# M2354 register map
File version: 1.0
Registers are 32-bit, read-write, reset 0x0 unless marked. A register's access mark holds for its fields unless they carry their own. Offsets are from the block's base; [hi:lo] are bit positions; {n}, {i} and the like mark numbered series; 'fields as' and 'values as' point back to an identical list.

## SCU_NS — SCU Register Map
Base 0x5002F000
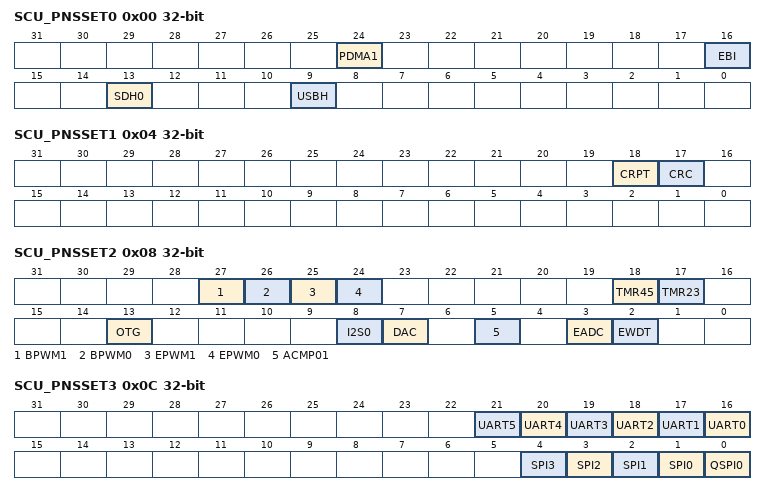
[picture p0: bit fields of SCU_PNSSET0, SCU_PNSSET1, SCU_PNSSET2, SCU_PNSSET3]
0x00 SCU_PNSSET0 — Peripheral Non-secure Attribution Set Register0 (0x4000_0000~0x4001_FFFF)
  [24] PDMA1 — Set PDMA1 to Non-secure State. Write 1 to set PDMA1 to non-secure state.
    0=PDMA1 is a secure module (default); 1=PDMA1 is a non-secure module
  [16] EBI — Set EBI to Non-secure State. Write 1 to set EBI to non-secure state.
    0=EBI is a secure module (default); 1=EBI is a non-secure module
  [13] SDH0 — Set SDH0 to Non-secure State. Write 1 to set SDH0 to non-secure state.
    0=SDH0 is a secure module (default); 1=SDH0 is a non-secure module
  [9] USBH — Set USBH to Non-secure State. Write 1 to set USBH to non-secure state.
    0=USBH is a secure module (default); 1=USBH is a non-secure module
0x04 SCU_PNSSET1 — Peripheral Non-secure Attribution Set Register1 (0x4002_0000~0x4003_FFFF)
  [18] CRPT — Set CRPT to Non-secure State
    0=CRPT is a secure module (default); 1=CRPT is a non-secure module
  [17] CRC — Set CRC to Non-secure State. Write 1 to set CRC to non-secure state.
    0=CRC is a secure module (default); 1=CRC is a non-secure module
0x08 SCU_PNSSET2 — Peripheral Non-secure Attribution Set Register2 (0x4004_0000~0x4005_FFFF)
  [27] BPWM1 — Set BPWM1 to Non-secure State. Write 1 to set BPWM1 to non-secure state.
    0=BPWM1 is a secure module (default); 1=BPWM1 is a non-secure module
  [26] BPWM0 — Set BPWM0 to Non-secure State. Write 1 to set BPWM0 to non-secure state.
    0=BPWM0 is a secure module (default); 1=BPWM0 is a non-secure module
  [25] EPWM1 — Set EPWM1 to Non-secure State. Write 1 to set EPWM1 to non-secure state.
    0=EPWM1 is a secure module (default); 1=EPWM1 is a non-secure module
  [24] EPWM0 — Set EPWM0 to Non-secure State. Write 1 to set EPWM0 to non-secure state.
    0=EPWM0 is a secure module (default); 1=EPWM0 is a non-secure module
  [18] TMR45 — Set TMR45 to Non-secure State. Write 1 to set TMR45 to non-secure state.
    0=TMR45 is a secure module (default); 1=TMR45 is a non-secure module
  [17] TMR23 — Set TMR23 to Non-secure State. Write 1 to set TMR23 to non-secure state.
    0=TMR23 is a secure module (default); 1=TMR23 is a non-secure module
  [13] OTG — Set OTG to Non-secure State. Write 1 to set OTG to non-secure state.
    0=OTG is a secure module (default); 1=OTG is a non-secure module
  [8] I2S0 — Set I2S0 to Non-secure State. Write 1 to set I2S0 to non-secure state.
    0=I2S0 is a secure module (default); 1=I2S0 is a non-secure module
  [7] DAC — Set DAC to Non-secure State. Write 1 to set DAC to non-secure state.
    0=DAC is a secure module (default); 1=DAC is a non-secure module
  [5] ACMP01 — Set ACMP01 to Non-secure State. Write 1 to set ACMP0, ACMP1 to non-secure state.
    0=ACMP0, ACMP1 are secure modules (default); 1=ACMP0, ACMP1 are non-secure modules
  [3] EADC — Set EADC to Non-secure State. Write 1 to set EADC to non-secure state.
    0=EADC is a secure module (default); 1=EADC is a non-secure module
  [2] EWDT — Set EWDT to Non-secure State. Write 1 to set EWDT to non-secure state.
    0=EWDT is a secure module (default); 1=EWDT is a non-secure module
0x0C SCU_PNSSET3 — Peripheral Non-secure Attribution Set Register3 (0x4006_0000~0x4007_FFFF)
  [n+16] UART{n} (n=0..5) — Set UART{n} to Non-secure State. Write 1 to set UART{n} to non-secure state.
    0=UART{n} is a secure module (default); 1=UART{n} is a non-secure module
  [n+1] SPI{n} (n=0..3) — Set SPI{n} to Non-secure State. Write 1 to set SPI{n} to non-secure state.
    0=SPI{n} is a secure module (default); 1=SPI{n} is a non-secure module
  [0] QSPI0 — Set QSPI0 to Non-secure State. Write 1 to set QSPI0 to non-secure state.
    0=QSPI0 is a secure module (default); 1=QSPI0 is a non-secure module
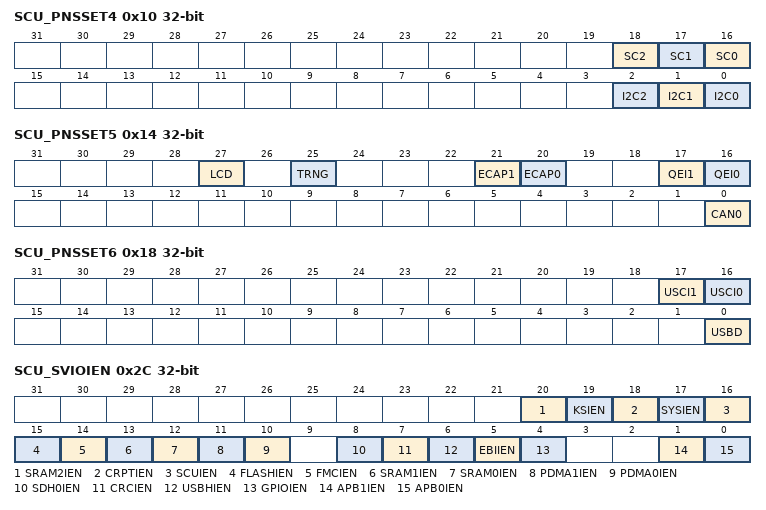
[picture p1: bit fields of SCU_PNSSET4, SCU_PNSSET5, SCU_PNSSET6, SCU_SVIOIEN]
0x10 SCU_PNSSET4 — Peripheral Non-secure Attribution Set Register4 (0x4008_0000~0x4009_FFFF)
  [18] SC2 — Set SC2 to Non-secure State. Write 1 to set SC2 to non-secure state.
    0=SC2 is a secure module (default); 1=SC2 is a non-secure module
  [17] SC1 — Set SC1 to Non-secure State. Write 1 to set SC1 to non-secure state.
    0=SC1 is a secure module (default); 1=SC1 is a non-secure module
  [16] SC0 — Set SC0 to Non-secure State. Write 1 to set SC0 to non-secure state.
    0=SC0 is a secure module (default); 1=SC0 is a non-secure module
  [2] I2C2 — Set I2C2 to Non-secure State. Write 1 to set I2C2 to non-secure state.
    0=I2C2 is a secure module (default); 1=I2C2 is a non-secure module
  [1] I2C1 — Set I2C1 to Non-secure State. Write 1 to set I2C1 to non-secure state.
    0=I2C1 is a secure module (default); 1=I2C1 is a non-secure module
  [0] I2C0 — Set I2C0 to Non-secure State. Write 1 to set I2C0 to non-secure state.
    0=I2C0 is a secure module (default); 1=I2C0 is a non-secure module
0x14 SCU_PNSSET5 — Peripheral Non-secure Attribution Set Register5 (0x400A_0000~0x400B_FFFF)
  [27] LCD — Set LCD to Non-secure State. Write 1 to set LCD to non-secure state.
    0=LCD is a secure module (default); 1=LCD is a non-secure module
  [25] TRNG — Set TRNG to Non-secure State. Write 1 to set TRNG to non-secure state.
    0=TRNG is a secure module (default); 1=TRNG is a non-secure module
  [21] ECAP1 — Set ECAP1 to Non-secure State. Write 1 to set ECAP1 to non-secure state.
    0=ECAP1 is a secure module (default); 1=ECAP1 is a non-secure module
  [20] ECAP0 — Set ECAP0 to Non-secure State. Write 1 to set ECAP0 to non-secure state.
    0=ECAP0 is a secure module (default); 1=ECAP0 is a non-secure module
  [17] QEI1 — Set QEI1 to Non-secure State. Write 1 to set QEI1 to non-secure state.
    0=QEI1 is a secure module (default); 1=QEI1 is a non-secure module
  [16] QEI0 — Set QEI0 to Non-secure State. Write 1 to set QEI0 to non-secure state.
    0=QEI0 is a secure module (default); 1=QEI0 is a non-secure module
  [0] CAN0 — Set CAN0 to Non-secure State. Write 1 to set CAN0 to non-secure state.
    0=CAN0 is a secure module (default); 1=CAN0 is a non-secure module
0x18 SCU_PNSSET6 — Peripheral Non-secure Attribution Set Register6 (0x400C_0000~0x400D_FFFF)
  [17] USCI1 — Set USCI1 to Non-secure State. Write 1 to set USCI1 to non-secure state.
    0=USCI1 is a secure module (default); 1=USCI1 is a non-secure module
  [16] USCI0 — Set USCI0 to Non-secure State. Write 1 to set USCI0 to non-secure state.
    0=USCI0 is a secure module (default); 1=USCI0 is a non-secure module
  [0] USBD — Set USBD to Non-secure State. Write 1 to set USBD to non-secure state.
    0=USBD is a secure module (default); 1=USBD is a non-secure module
0x24 SCU_SRAMNSSET — SRAM Non-secure Attribution Set Register
  [14:0] SECn — Set SRAM Section n to Non-secure State. Write 1 to set SRAM section n to non-secure state. Write 0 is ignored. Size per section is 16 Kbytes. Secure SRAM section n is 0x2000_0000+0x4000*n to 0x2000_0000+0x4000*(n+1)-0x1. Non-secure SRAM section n is 0x3000_0000+0x4000*n to 0x3000_0000+0x4000*(n+1)-0x1
    0=SRAM Section n is secure (default); 1=SRAM Section n is non-secure
0x28 SCU_FNSADDR ro reset not defined — Flash Non-secure Boundary Address Register
  [31:0] FNSADDR — Flash Non-secure Boundary Address. Indicate the base address of Non-secure region set in user configuration. Refer to FMC section for more details.
0x2C SCU_SVIOIEN — Security Violation Interrupt Enable Register
  [20] SRAM2IEN — SRAM2 Security Violation Interrupt Enable Bit
    0=Interrupt triggered from security violation of SRAM2 Disabled; 1=Interrupt triggered from security violation of SRAM2 Enabled
  [19] KSIEN — KS Security Violation Interrupt Enable Bit
    0=Interrupt triggered from security violation of keystore Disabled; 1=Interrupt triggered from security violation of keystore Enabled
  [18] CRPTIEN — CRPT Security Violation Interrupt Enable Bit
    0=Interrupt triggered from security violation of crypto Disabled; 1=Interrupt triggered from security violation of crypto Enabled
  [17] SYSIEN — SYS Security Violation Interrupt Enable Bit
    0=Interrupt triggered from security violation of system manager Disabled; 1=Interrupt triggered from security violation of system manager Enabled
  [16] SCUIEN — SCU Security Violation Interrupt Enable Bit
    0=Interrupt triggered from security violation of SCU Disabled; 1=Interrupt triggered from security violation of SCU Enabled
  [15] FLASHIEN — FLASH Security Violation Interrupt Enable Bit
    0=Interrupt triggered from security violation of Flash data Disabled; 1=Interrupt triggered from security violation of Flash data Enabled
  [14] FMCIEN — FMC Security Violation Interrupt Enable Bit
    0=Interrupt triggered from security violation of FMC Disabled; 1=Interrupt triggered from security violation of FMC Enabled
  [13] SRAM1IEN — SRAM Bank 1 Security Violation Interrupt Enable Bit
    0=Interrupt triggered from security violation of SRAM bank1 Disabled; 1=Interrupt triggered from security violation of SRAM bank1 Enabled
  [12] SRAM0IEN — SRAM Bank 0 Security Violation Interrupt Enable Bit
    0=Interrupt triggered from security violation of SRAM bank0 Disabled; 1=Interrupt triggered from security violation of SRAM bank0 Enabled
  [11] PDMA1IEN — PDMA1 Security Violation Interrupt Enable Bit
    0=Interrupt triggered from security violation of PDMA1 Disabled; 1=Interrupt triggered from security violation of PDMA1 Enabled
  [10] PDMA0IEN — PDMA0 Security Violation Interrupt Enable Bit
    0=Interrupt triggered from security violation of PDMA0 Disabled; 1=Interrupt triggered from security violation of PDMA0 Enabled
  [8] SDH0IEN — SDH0 Security Violation Interrupt Enable Bit
    0=Interrupt triggered from security violation of SD host 0 Disabled; 1=Interrupt triggered from security violation of SD host 0 Enabled
  [7] CRCIEN — CRC Security Violation Interrupt Enable Bit
    0=Interrupt triggered from security violation of CRC Disabled; 1=Interrupt triggered from security violation of CRC Enabled
  [6] USBHIEN — USBH Security Violation Interrupt Enable Bit
    0=Interrupt triggered from security violation of USB host Disabled; 1=Interrupt triggered from security violation of USB host Enabled
  [5] EBIIEN — EBI Security Violation Interrupt Enable Bit
    0=Interrupt triggered from security violation of EBI Disabled; 1=Interrupt triggered from security violation of EBI Enabled
  [4] GPIOIEN — GPIO Security Violation Interrupt Enable Bit
    0=Interrupt triggered from security violation of GPIO Disabled; 1=Interrupt triggered from security violation of GPIO Enabled
  [1] APB1IEN — APB1 Security Violation Interrupt Enable Bit
    0=Interrupt triggered from security violation of APB1 Disabled; 1=Interrupt triggered from security violation of APB1 Enabled
  [0] APB0IEN — APB0 Security Violation Interrupt Enable Bit
    0=Interrupt triggered from security violation of APB0 Disabled; 1=Interrupt triggered from security violation of APB0 Enabled
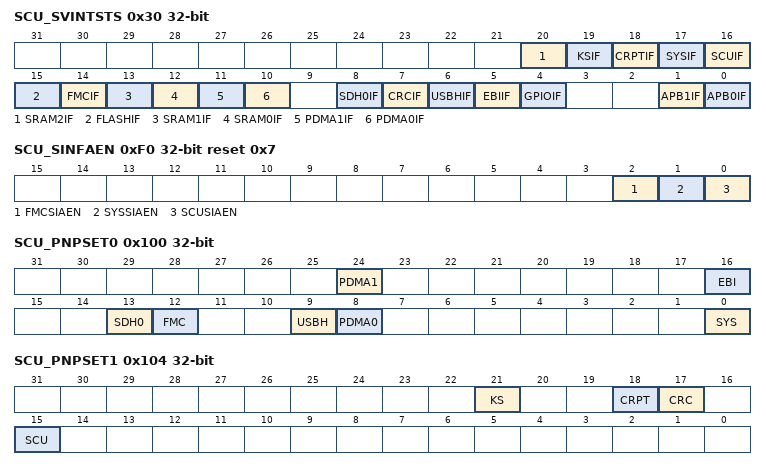
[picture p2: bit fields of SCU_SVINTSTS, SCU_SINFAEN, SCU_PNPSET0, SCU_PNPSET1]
0x30 SCU_SVINTSTS — Security Violation Interrupt Status Register
  [20] SRAM2IF — SRAM Bank 2 Security Violation Interrupt Status. Note: Write 1 to clear the interrupt flag.
    0=No SRAM Bank 2 violation interrupt event; 1=There is at least a SRAM Bank 2 violation interrupt event
  [19] KSIF — KS Security Violation Interrupt Status. Note: Write 1 to clear the interrupt flag.
    0=No KS violation interrupt event; 1=There is at least a KS violation interrupt event
  [18] CRPTIF — CRPT Security Violation Interrupt Status. Note: Write 1 to clear the interrupt flag.
    0=No CRPT violation interrupt event; 1=There is at least a CRPT violation interrupt event
  [17] SYSIF — SYS Security Violation Interrupt Status. Note: Write 1 to clear the interrupt flag.
    0=No SYS violation interrupt event; 1=There is at least a SYS violation interrupt event
  [16] SCUIF — SCU Security Violation Interrupt Status. Note: Write 1 to clear the interrupt flag.
    0=No SCU violation interrupt event; 1=There is at least a SCU violation interrupt event
  [15] FLASHIF — FLASH Security Violation Interrupt Status. Note: Write 1 to clear the interrupt flag.
    0=No FLASH violation interrupt event; 1=There is at least a FLASH violation interrupt event
  [14] FMCIF — FMC Security Violation Interrupt Status. Note: Write 1 to clear the interrupt flag.
    0=No FMC violation interrupt event; 1=There is at least a FMC violation interrupt event
  [13] SRAM1IF — SRAM Bank 1 Security Violation Interrupt Status. Note: Write 1 to clear the interrupt flag.
    0=No SRAM Bank 1 violation interrupt event; 1=There is at least a SRAM Bank 1 violation interrupt event
  [12] SRAM0IF — SRAM Bank 0 Security Violation Interrupt Status. Note: Write 1 to clear the interrupt flag.
    0=No SRAM Bank 0 violation interrupt event; 1=There is at least a SRAM Bank 0 violation interrupt event
  [11] PDMA1IF — PDMA1 Security Violation Interrupt Status. Note: Write 1 to clear the interrupt flag.
    0=No PDMA1 violation interrupt event; 1=There is at least a PDMA1 violation interrupt event
  [10] PDMA0IF — PDMA0 Security Violation Interrupt Status. Note: Write 1 to clear the interrupt flag.
    0=No PDMA0 violation interrupt event; 1=There is at least a PDMA0 violation interrupt event
  [8] SDH0IF — SDH0 Security Violation Interrupt Status. Note: Write 1 to clear the interrupt flag.
    0=No SDH0 violation interrupt event; 1=There is at least a SDH0 violation interrupt event
  [7] CRCIF — CRC Security Violation Interrupt Status. Note: Write 1 to clear the interrupt flag.
    0=No CRC violation interrupt event; 1=There is at least a CRC violation interrupt event
  [6] USBHIF — USBH Security Violation Interrupt Status. Note: Write 1 to clear the interrupt flag.
    0=No USBH violation interrupt event; 1=There is at least a USBH violation interrupt event
  [5] EBIIF — EBI Security Violation Interrupt Status. Note: Write 1 to clear the interrupt flag.
    0=No EBI violation interrupt event; 1=There is at least a EBI violation interrupt event
  [4] GPIOIF — GPIO Security Violation Interrupt Status. Note: Write 1 to clear the interrupt flag.
    0=No GPIO violation interrupt event; 1=There is at least a GPIO violation interrupt event
  [1] APB1IF — APB1 Security Violation Interrupt Status. Note: Write 1 to clear the interrupt flag.
    0=No APB1 violation interrupt event; 1=There is at least a APB1 violation interrupt event
  [0] APB0IF — APB0 Security Violation Interrupt Status. Note: Write 1 to clear the interrupt flag.
    0=No APB0 violation interrupt event; 1=There is at least a APB0 violation interrupt event
0x34 SCU_APB0VSRC ro (reset mask 0xFFFFFFF0) — APB0 Security Policy Violation Source
  [3:0] MASTER — Master Violating Security Policy. Indicate which master invokes the security violation. Others is undefined.
    0=core processor; 3=PDMA0; 4=SDH0; 5=CRYPTO; 6=USH; 11=PDMA1
0x38 SCU_APB0VA ro reset not defined — APB0 Violation Address
  [31:0] VIOADDR — Violation Address. Indicate the target address of the access, which invokes the security violation.
0x3C SCU_APB1VSRC ro (reset mask 0xFFFFFFF0) — APB1 Security Policy Violation Source
  fields as SCU_APB0VSRC
0x40 SCU_APB1VA ro reset not defined — APB1 Violation Address
  fields as SCU_APB0VA
0x44 SCU_GPIOVSRC ro (reset mask 0xFFFFFFF0) — GPIO Security Policy Violation Source
  fields as SCU_APB0VSRC
0x48 SCU_GPIOVA ro reset not defined — GPIO Violation Address
  fields as SCU_APB0VA
0x4C SCU_EBIVSRC ro (reset mask 0xFFFFFFF0) — EBI Security Policy Violation Source
  fields as SCU_APB0VSRC
0x50 SCU_EBIVA ro reset not defined — EBI Violation Address
  fields as SCU_APB0VA
0x54 SCU_USBHVSRC ro (reset mask 0xFFFFFFF0) — USBH Security Policy Violation Source
  fields as SCU_APB0VSRC
0x58 SCU_USBHVA ro reset not defined — USBH Violation Address
  fields as SCU_APB0VA
0x5C SCU_CRCVSRC ro (reset mask 0xFFFFFFF0) — CRC Security Policy Violation Source
  fields as SCU_APB0VSRC
0x60 SCU_CRCVA ro reset not defined — CRC Violation Address
  fields as SCU_APB0VA
0x64 SCU_SD0VSRC ro (reset mask 0xFFFFFFF0) — SDH0 Security Policy Violation Source
  fields as SCU_APB0VSRC
0x68 SCU_SD0VA ro reset not defined — SDH0 Violation Address
  fields as SCU_APB0VA
0x74 SCU_PDMA0VSRC ro (reset mask 0xFFFFFFF0) — PDMA0 Security Policy Violation Source
  fields as SCU_APB0VSRC
0x78 SCU_PDMA0VA ro reset not defined — PDMA0 Violation Address
  fields as SCU_APB0VA
0x7C SCU_PDMA1VSRC ro (reset mask 0xFFFFFFF0) — PDMA1 Security Policy Violation Source
  fields as SCU_APB0VSRC
0x80 SCU_PDMA1VA ro reset not defined — PDMA1 Violation Address
  fields as SCU_APB0VA
0x84 SCU_SRAM0VSRC ro (reset mask 0xFFFFFFF0) — SRAM0 Security Policy Violation Source
  fields as SCU_APB0VSRC
0x88 SCU_SRAM0VA ro reset not defined — SRAM0 Violation Address
  fields as SCU_APB0VA
0x8C SCU_SRAM1VSRC ro (reset mask 0xFFFFFFF0) — SRAM1 Security Policy Violation Source
  fields as SCU_APB0VSRC
0x90 SCU_SRAM1VA ro reset not defined — SRAM1 Violation Address
  fields as SCU_APB0VA
0x94 SCU_FMCVSRC ro (reset mask 0xFFFFFFF0) — FMC Security Policy Violation Source
  fields as SCU_APB0VSRC
0x98 SCU_FMCVA ro reset not defined — FMC Violation Address
  fields as SCU_APB0VA
0x9C SCU_FLASHVSRC ro (reset mask 0xFFFFFFF0) — Flash Security Policy Violation Source
  fields as SCU_APB0VSRC
0xA0 SCU_FLASHVA ro reset not defined — Flash Violation Address
  fields as SCU_APB0VA
0xA4 SCU_SCUVSRC ro (reset mask 0xFFFFFFF0) — SCU Security Policy Violation Source
  fields as SCU_APB0VSRC
0xA8 SCU_SCUVA ro reset not defined — SCU Violation Address
  fields as SCU_APB0VA
0xAC SCU_SYSVSRC ro (reset mask 0xFFFFFFF0) — System Security Policy Violation Source
  fields as SCU_APB0VSRC
0xB0 SCU_SYSVA ro reset not defined — System Violation Address
  fields as SCU_APB0VA
0xB4 SCU_CRPTVSRC ro (reset mask 0xFFFFFFF0) — Crypto Security Policy Violation Source
  fields as SCU_APB0VSRC
0xB8 SCU_CRPTVA ro reset not defined — Crypto Violation Address
  fields as SCU_APB0VA
0xBC SCU_KSVSRC ro (reset mask 0xFFFFFFF0) — KS Security Policy Violation Source
  fields as SCU_APB0VSRC
0xC0 SCU_KSVA ro reset not defined — KS Violation Address
  fields as SCU_APB0VA
0xC4 SCU_SRAM2VSRC ro (reset mask 0xFFFFFFF0) — SRAM2 Security Policy Violation Source
  fields as SCU_APB0VSRC
0xC8 SCU_SRAM2VA ro reset not defined — SRAM2 Violation Address
  fields as SCU_APB0VA
0xF0 SCU_SINFAEN reset 0x7 — Shared Information Access Enable Register
  [2] FMCSIAEN — FMC Shared Information Access Enable Bit
    0=Non-secure CPU access FMC Shared information Disabled; 1=Non-secure CPU access FMC Shared information Enabled
  [1] SYSSIAEN — SYS Shared Information Access Enable Bit. Note: Include clock information.
    0=Non-secure CPU access SYS Shared information Disabled; 1=Non-secure CPU access SYS Shared information Enabled
  [0] SCUSIAEN — SCU Shared Information Access Enable Bit
    0=Non-secure CPU access SCU Shared information Disabled; 1=Non-secure CPU access SCU Shared information Enabled
0x100 SCU_PNPSET0 — Peripheral Non-privileged Attribution Set Register0 (0x4000_0000~0x4001_FFFF)
  [24] PDMA1 — Set PDMA1 to Non-privileged State
    0=PDMA1 is a privileged module (default); 1=PDMA1 is a non-privileged module
  [16] EBI — Set EBI to Non-privileged State
    0=EBI is a privileged module (default); 1=EBI is a non-privileged module
  [13] SDH0 — Set SDH0 to Non-privileged State
    0=SDH0 is a privileged module (default); 1=SDH0 is a non-privileged module
  [12] FMC — Set FMC to Non-privileged State
    0=FMC is a privileged module (default); 1=FMC is a non-privileged module
  [9] USBH — Set USBH to Non-privileged State
    0=USBH is a privileged module (default); 1=USBH is a non-privileged module
  [8] PDMA0 — Set PDMA0 to Non-privileged State
    0=PDMA0 is a privileged module (default); 1=PDMA0 is a non-privileged module
  [0] SYS — Set SYS to Non-privileged State
    0=SYS is a privileged module (default); 1=SYS is a non-privileged module
0x104 SCU_PNPSET1 — Peripheral Non-privileged Attribution Set Register1 (0x4002_0000~0x4003_FFFF)
  [21] KS — Set KS to Non-privileged State
    0=KS is a privileged module (default); 1=KS is a non-privileged module
  [18] CRPT — Set CRPT to Non-privileged State
    0=CRPT is a privileged module (default); 1=CRPT is a non-privileged module
  [17] CRC — Set CRC to Non-privileged State
    0=CRC is a privileged module (default); 1=CRC is a non-privileged module
  [15] SCU — Set SCU to Non-privileged State
    0=SCU is a privileged module (default); 1=SCU is a non-privileged module
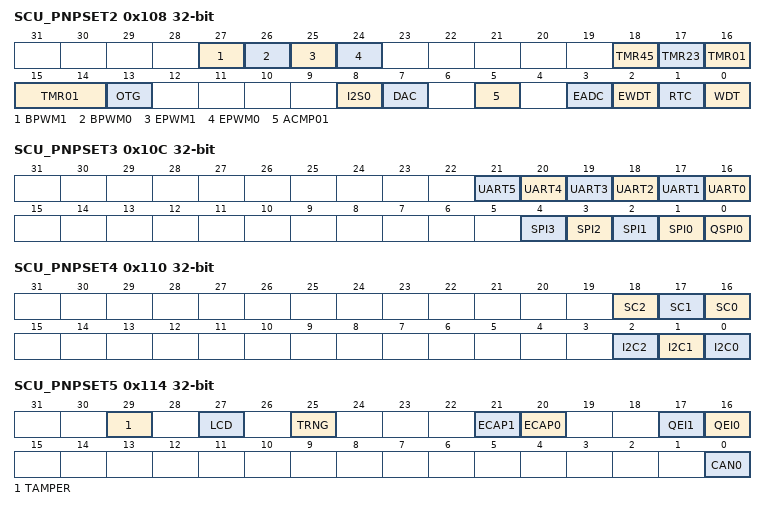
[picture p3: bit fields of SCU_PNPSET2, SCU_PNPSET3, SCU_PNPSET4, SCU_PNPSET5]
0x108 SCU_PNPSET2 — Peripheral Non-privileged Attribution Set Register2 (0x4004_0000~0x4005_FFFF)
  [27] BPWM1 — Set BPWM1 to Non-privileged State
    0=BPWM1 is a privileged module (default); 1=BPWM1 is a non-privileged module
  [26] BPWM0 — Set BPWM0 to Non-privileged State
    0=BPWM0 is a privileged module (default); 1=BPWM0 is a non-privileged module
  [25] EPWM1 — Set EPWM1 to Non-privileged State
    0=EPWM1 is a privileged module (default); 1=EPWM1 is a non-privileged module
  [24] EPWM0 — Set EPWM0 to Non-privileged State
    0=EPWM0 is a privileged module (default); 1=EPWM0 is a non-privileged module
  [18] TMR45 — Set TMR45 to Non-privileged State
    0=TMR45 is a privileged module (default); 1=TMR45 is a non-privileged module
  [17] TMR23 — Set TMR23 to Non-privileged State
    0=TMR23 is a privileged module (default); 1=TMR23 is a non-privileged module
  [16:14] TMR01 — Set TMR01 to Non-privileged State
    0=TMR01 is a privileged module (default); 1=TMR01 is a non-privileged module
  [13] OTG — Set OTG to Non-privileged State
    0=OTG is a privileged module (default); 1=OTG is a non-privileged module
  [8] I2S0 — Set I2S0 to Non-privileged State
    0=I2S0 is a privileged module (default); 1=I2S0 is a non-privileged module
  [7] DAC — Set DAC to Non-privileged State
    0=DAC is a privileged module (default); 1=DAC is a non-privileged module
  [5] ACMP01 — Set ACMP01 to Non-privileged State
    0=ACMP0, ACMP1 are privileged modules (default); 1=ACMP0, ACMP1 are non-privileged modules
  [3] EADC — Set EADC to Non-privileged State
    0=EADC is a privileged module (default); 1=EADC is a non-privileged module
  [2] EWDT — Set EWDT to Non-privileged State
    0=EWDT is a privileged module (default); 1=EWDT is a non-privileged module
  [1] RTC — Set RTC to Non-privileged State
    0=RTC is a privileged module (default); 1=RTC is a non-privileged module
  [0] WDT — Set WDT to Non-privileged State
    0=WDT is a privileged module (default); 1=WDT is a non-privileged module
0x10C SCU_PNPSET3 — Peripheral Non-privileged Attribution Set Register3 (0x4006_0000~0x4007_FFFF)
  [n+16] UART{n} (n=0..5) — Set UART{n} to Non-privileged State
    0=UART{n} is a privileged module (default); 1=UART{n} is a non-privileged module
  [n+1] SPI{n} (n=0..3) — Set SPI{n} to Non-privileged State
    0=SPI{n} is a privileged module (default); 1=SPI{n} is a non-privileged module
  [0] QSPI0 — Set QSPI0 to Non-privileged State
    0=QSPI0 is a privileged module (default); 1=QSPI0 is a non-privileged module
0x110 SCU_PNPSET4 — Peripheral Non-privileged Attribution Set Register4 (0x4008_0000~0x4009_FFFF)
  [18] SC2 — Set SC2 to Non-privileged State
    0=SC2 is a privileged module (default); 1=SC2 is a non-privileged module
  [17] SC1 — Set SC1 to Non-privileged State
    0=SC1 is a privileged module (default); 1=SC1 is a non-privileged module
  [16] SC0 — Set SC0 to Non-privileged State
    0=SC0 is a privileged module (default); 1=SC0 is a non-privileged module
  [2] I2C2 — Set I2C2 to Non-privileged State
    0=I2C2 is a privileged module (default); 1=I2C2 is a non-privileged module
  [1] I2C1 — Set I2C1 to Non-privileged State
    0=I2C1 is a privileged module (default); 1=I2C1 is a non-privileged module
  [0] I2C0 — Set I2C0 to Non-privileged State
    0=I2C0 is a privileged module (default); 1=I2C0 is a non-privileged module
0x114 SCU_PNPSET5 — Peripheral Non-privileged Attribution Set Register5 (0x400A_0000~0x400B_FFFF)
  [29] TAMPER — Set TAMPER to Non-privileged State
    0=TAMPER is a privileged module (default); 1=TAMPER is a non-privileged module
  [27] LCD — Set LCD to Non-privileged State
    0=LCD is a privileged module (default); 1=LCD is a non-privileged module
  [25] TRNG — Set TRNG to Non-privileged State
    0=TRNG is a privileged module (default); 1=TRNG is a non-privileged module
  [21] ECAP1 — Set ECAP1 to Non-privileged State
    0=ECAP1 is a privileged module (default); 1=ECAP1 is a non-privileged module
  [20] ECAP0 — Set ECAP0 to Non-privileged State
    0=ECAP0 is a privileged module (default); 1=ECAP0 is a non-privileged module
  [17] QEI1 — Set QEI1 to Non-privileged State
    0=QEI1 is a privileged module (default); 1=QEI1 is a non-privileged module
  [16] QEI0 — Set QEI0 to Non-privileged State
    0=QEI0 is a privileged module (default); 1=QEI0 is a non-privileged module
  [0] CAN0 — Set CAN0 to Non-privileged State
    0=CAN0 is a privileged module (default); 1=CAN0 is a non-privileged module
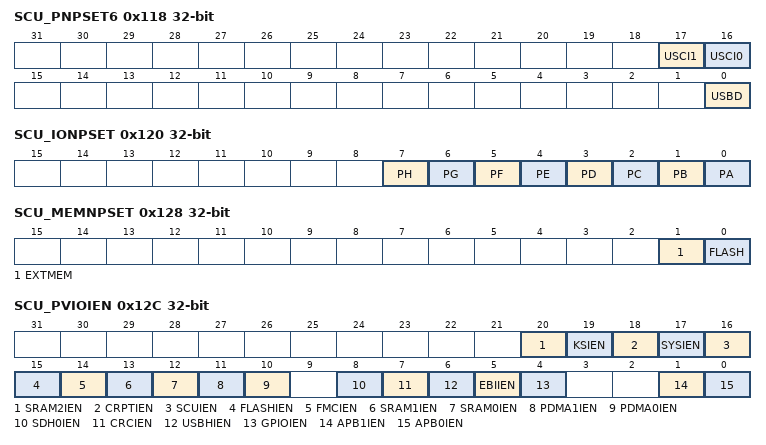
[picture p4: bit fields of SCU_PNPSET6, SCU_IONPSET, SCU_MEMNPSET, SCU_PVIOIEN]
0x118 SCU_PNPSET6 — Peripheral Non-privileged Attribution Set Register6 (0x400C_0000~0x400D_FFFF)
  [17] USCI1 — Set USCI1 to Non-privileged State
    0=USCI1 is a privileged module (default); 1=USCI1 is a non-privileged module
  [16] USCI0 — Set USCI0 to Non-privileged State
    0=USCI0 is a privileged module (default); 1=USCI0 is a non-privileged module
  [0] USBD — Set USBD to Non-privileged State
    0=USBD is a privileged module (default); 1=USBD is a non-privileged module
0x120 SCU_IONPSET — I/O Non-privileged Attribution Set Register
  [7] PH — Set GPIO Port H to Non-privileged State
    0=GPIO port H is privileged (default); 1=GPIO port H is non-privileged
  [6] PG — Set GPIO Port G to Non-privileged State
    0=GPIO port G is privileged (default); 1=GPIO port G is non-privileged
  [5] PF — Set GPIO Port F to Non-privileged State
    0=GPIO port F is privileged (default); 1=GPIO port F is non-privileged
  [4] PE — Set GPIO Port E to Non-privileged State
    0=GPIO port E is privileged (default); 1=GPIO port E is non-privileged
  [3] PD — Set GPIO Port D to Non-privileged State
    0=GPIO port D is privileged (default); 1=GPIO port D is non-privileged
  [2] PC — Set GPIO Port C to Non-privileged State
    0=GPIO port C is privileged (default); 1=GPIO port C is non-privileged
  [1] PB — Set GPIO Port B to Non-privileged State
    0=GPIO port B is privileged (default); 1=GPIO port B is non-privileged
  [0] PA — Set GPIO Port a to Non-privileged State
    0=GPIO port A is privileged (default); 1=GPIO port A is non-privileged
0x124 SCU_SRAMNPSET — SRAM Non-privileged Attribution Set Register
  [15:0] SECn — Set SRAM Section n to Non-privileged State. Size per section is 16 Kbytes. Secure SRAM section n is 0x2000_0000+0x4000*n to 0x2000_0000+0x4000*(n+1)-0x1. Non-secure SRAM section n is 0x3000_0000+0x4000*n to 0x3000_0000+0x4000*(n+1)-0x1
    0=SRAM Section n is privileged (default); 1=SRAM Section n is non-privileged
0x128 SCU_MEMNPSET — Other Memory Non-privileged Attribution Set Register
  [1] EXTMEM — Set External Memory (EBI Memory) to Non-privileged State. Set the privileged state of memory ranging from 0x6000_0000 to 0x7FFF_FFFF.
    0=External Memory is set to privileged (default); 1=External Memory is set to non-privileged
  [0] FLASH — Set Flash to Non-privileged State. Set the privileged state of memory ranging from 0x0000_0000 to 0x1FFF_FFFF.
    0=Flash is set to privileged (default); 1=Flash is set to non-privileged
0x12C SCU_PVIOIEN — Privileged Violation Interrupt Enable Register
  [20] SRAM2IEN — SRAM2 Privileged Violation Interrupt Enable Bit
    0=Interrupt triggered from privileged violation of SRAM2 Disabled; 1=Interrupt triggered from privileged violation of SRAM2 Enabled
  [19] KSIEN — KS Privileged Violation Interrupt Enable Bit
    0=Interrupt triggered from privileged violation of keystore Disabled; 1=Interrupt triggered from privileged violation of keystore Enabled
  [18] CRPTIEN — CRPT Privileged Violation Interrupt Enable Bit
    0=Interrupt triggered from privileged violation of crypto Disabled; 1=Interrupt triggered from privileged violation of crypto Enabled
  [17] SYSIEN — SYS Privileged Violation Interrupt Enable Bit
    0=Interrupt triggered from privileged violation of system manager Disabled; 1=Interrupt triggered from privileged violation of system manager Enabled
  [16] SCUIEN — SCU Privileged Violation Interrupt Enable Bit
    0=Interrupt triggered from privileged violation of SCU Disabled; 1=Interrupt triggered from privileged violation of SCU Enabled
  [15] FLASHIEN — FLASH Privileged Violation Interrupt Enable Bit
    0=Interrupt triggered from privileged violation of Flash data Disabled; 1=Interrupt triggered from privileged violation of Flash data Enabled
  [14] FMCIEN — FMC Privileged Violation Interrupt Enable Bit
    0=Interrupt triggered from privileged violation of FMC Disabled; 1=Interrupt triggered from privileged violation of FMC Enabled
  [13] SRAM1IEN — SRAM Bank 1 Privileged Violation Interrupt Enable Bit
    0=Interrupt triggered from privileged violation of SRAM bank1 Disabled; 1=Interrupt triggered from privileged violation of SRAM bank1 Enabled
  [12] SRAM0IEN — SRAM Bank 0 Privileged Violation Interrupt Enable Bit
    0=Interrupt triggered from privileged violation of SRAM bank0 Disabled; 1=Interrupt triggered from privileged violation of SRAM bank0 Enabled
  [11] PDMA1IEN — PDMA1 Privileged Violation Interrupt Enable Bit
    0=Interrupt triggered from privileged violation of PDMA1 Disabled; 1=Interrupt triggered from privileged violation of PDMA1 Enabled
  [10] PDMA0IEN — PDMA0 Privileged Violation Interrupt Enable Bit
    0=Interrupt triggered from privileged violation of PDMA0 Disabled; 1=Interrupt triggered from privileged violation of PDMA0 Enabled
  [8] SDH0IEN — SDH0 Privileged Violation Interrupt Enable Bit
    0=Interrupt triggered from privileged violation of SD host 0 Disabled; 1=Interrupt triggered from privileged violation of SD host 0 Enabled
  [7] CRCIEN — CRC Privileged Violation Interrupt Enable Bit
    0=Interrupt triggered from privileged violation of CRC Disabled; 1=Interrupt triggered from privileged violation of CRC Enabled
  [6] USBHIEN — USBH Privileged Violation Interrupt Enable Bit
    0=Interrupt triggered from privileged violation of USB host Disabled; 1=Interrupt triggered from privileged violation of USB host Enabled
  [5] EBIIEN — EBI Privileged Violation Interrupt Enable Bit
    0=Interrupt triggered from privileged violation of EBI Disabled; 1=Interrupt triggered from privileged violation of EBI Enabled
  [4] GPIOIEN — GPIO Privileged Violation Interrupt Enable Bit
    0=Interrupt triggered from privileged violation of GPIO Disabled; 1=Interrupt triggered from privileged violation of GPIO Enabled
  [1] APB1IEN — APB1 Privileged Violation Interrupt Enable Bit
    0=Interrupt triggered from privileged violation of APB1 Disabled; 1=Interrupt triggered from privileged violation of APB1 Enabled
  [0] APB0IEN — APB0 Privileged Violation Interrupt Enable Bit
    0=Interrupt triggered from privileged violation of APB0 Disabled; 1=Interrupt triggered from privileged violation of APB0 Enabled
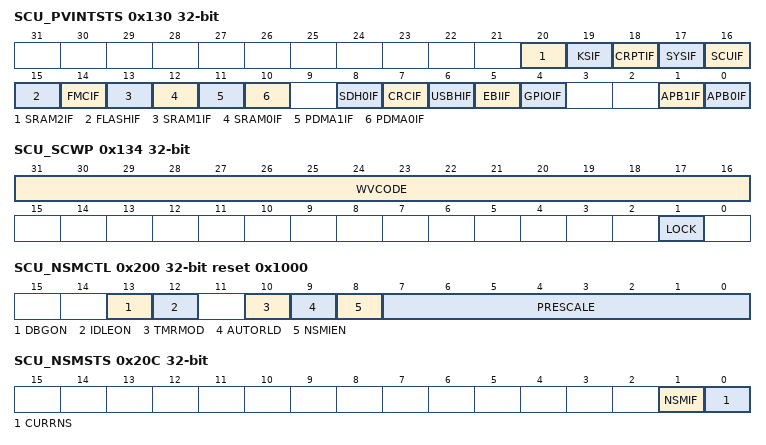
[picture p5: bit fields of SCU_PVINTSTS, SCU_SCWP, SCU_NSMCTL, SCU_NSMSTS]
0x130 SCU_PVINTSTS — Privileged Violation Interrupt Status Register
  [20] SRAM2IF — SRAM Bank 2 Privileged Violation Interrupt Status. Note: Write 1 to clear the interrupt flag.
    0=No SRAM Bank 2 violation interrupt event; 1=There is SRAM Bank 2 violation interrupt event
  [19] KSIF — KS Privileged Violation Interrupt Status. Note: Write 1 to clear the interrupt flag.
    0=No KS violation interrupt event; 1=There is KS violation interrupt event
  [18] CRPTIF — CRPT Privileged Violation Interrupt Status. Note: Write 1 to clear the interrupt flag.
    0=No CRPT violation interrupt event; 1=There is CRPT violation interrupt event
  [17] SYSIF — SYS Privileged Violation Interrupt Status. Note: Write 1 to clear the interrupt flag.
    0=No SYS violation interrupt event; 1=There is SYS violation interrupt event
  [16] SCUIF — SCU Privileged Violation Interrupt Status. Note: Write 1 to clear the interrupt flag.
    0=No SCU violation interrupt event; 1=There is SCU violation interrupt event
  [15] FLASHIF — FLASH Privileged Violation Interrupt Status. Note: Write 1 to clear the interrupt flag.
    0=No FLASH violation interrupt event; 1=There is FLASH violation interrupt event
  [14] FMCIF — FMC Privileged Violation Interrupt Status. Note: Write 1 to clear the interrupt flag.
    0=No FMC violation interrupt event; 1=There is FMC violation interrupt event
  [13] SRAM1IF — SRAM Bank 1 Privileged Violation Interrupt Status. Note: Write 1 to clear the interrupt flag.
    0=No SRAM1 violation interrupt event; 1=There is SRAM1 violation interrupt event
  [12] SRAM0IF — SRAM0 Privileged Violation Interrupt Status. Note: Write 1 to clear the interrupt flag.
    0=No SRAM0 violation interrupt event; 1=There is SRAM0 violation interrupt event
  [11] PDMA1IF — PDMA1 Privileged Violation Interrupt Status. Note: Write 1 to clear the interrupt flag.
    0=No PDMA1 violation interrupt event; 1=There is PDMA1 violation interrupt event
  [10] PDMA0IF — PDMA0 Privileged Violation Interrupt Status. Note: Write 1 to clear the interrupt flag.
    0=No PDMA0 violation interrupt event; 1=There is PDMA0 violation interrupt event
  [8] SDH0IF — SDH0 Privileged Violation Interrupt Status. Note: Write 1 to clear the interrupt flag.
    0=No SDH0 violation interrupt event; 1=There is SDH0 violation interrupt event
  [7] CRCIF — CRC Privileged Violation Interrupt Status. Note: Write 1 to clear the interrupt flag.
    0=No CRC violation interrupt event; 1=There is CRC violation interrupt event
  [6] USBHIF — USBH Privileged Violation Interrupt Status. Note: Write 1 to clear the interrupt flag.
    0=No USBH violation interrupt event; 1=There is USBH violation interrupt event
  [5] EBIIF — EBI Privileged Violation Interrupt Status. Note: Write 1 to clear the interrupt flag.
    0=No EBI violation interrupt event; 1=There is EBI violation interrupt event
  [4] GPIOIF — GPIO Privileged Violation Interrupt Status. Note: Write 1 to clear the interrupt flag.
    0=No GPIO violation interrupt event; 1=There is GPIO violation interrupt event
  [1] APB1IF — APB1 Privileged Violation Interrupt Status. Note: Write 1 to clear the interrupt flag.
    0=No APB1 violation interrupt event; 1=There is APB1 violation interrupt event
  [0] APB0IF — APB0 Privileged Violation Interrupt Status. Note: Write 1 to clear the interrupt flag.
    0=No APB0 violation interrupt event; 1=There is APB0 violation interrupt event
0x134 SCU_SCWP — Security Configuration Write Protection Register
  [31:16] WVCODE — Write Verify Code. Read operation: Reserved, all zeros. Write operation:
    0x475A=The write verify code, 0x475A, is needed to do a valid write to SCU_SCWP
  [1] LOCK — Enable Write Protection Lock Bit (Write One Only). Note: This bit cannot be cleared to 0 without a system-level reset after set to one.
    0=Write protection lock Disabled; 1=Write protection Enabled and locked
0x140 SCU_IONSSET0 — I/O Non-secure Attribution Set Register0
  [15:0] PA — Set GPIO Port A to Non-secure State. Write 1 to set PA to non-secure state. Each bit configures one pin in GPIO port A.
    0=GPIO port A is secure (default); 1=GPIO port A is non-secure
0x144 SCU_IONSSET1 — I/O Non-secure Attribution Set Register1
  [15:0] PB — Set GPIO Port B to Non-secure State. Write 1 to set PB to non-secure state. Each bit configures one pin in GPIO port B.
    0=GPIO port B is secure (default); 1=GPIO port B is non-secure
0x148 SCU_IONSSET2 — I/O Non-secure Attribution Set Register2
  [15:0] PC — Set GPIO Port C to Non-secure State. Write 1 to set PC to non-secure state. Each bit configures one pin in GPIO port C.
    0=GPIO port C is secure (default); 1=GPIO port C is non-secure
0x14C SCU_IONSSET3 — I/O Non-secure Attribution Set Register3
  [15:0] PD — Set GPIO Port D to Non-secure State. Write 1 to set PD to non-secure state. Each bit configures one pin in GPIO port D.
    0=GPIO port D is secure (default); 1=GPIO port D is non-secure
0x150 SCU_IONSSET4 — I/O Non-secure Attribution Set Register4
  [15:0] PE — Set GPIO Port E to Non-secure State. Write 1 to set PE to non-secure state. Each bit configures one pin in GPIO port E.
    0=GPIO port E is secure (default); 1=GPIO port E is non-secure
0x154 SCU_IONSSET5 — I/O Non-secure Attribution Set Register5
  [15:0] PF — Set GPIO Port F to Non-secure State. Write 1 to set PF to non-secure state. Each bit configures one pin in GPIO port F.
    0=GPIO port F is secure (default); 1=GPIO port F is non-secure
0x158 SCU_IONSSET6 — I/O Non-secure Attribution Set Register6
  [15:0] PG — Set GPIO Port G to Non-secure State. Write 1 to set PG to non-secure state. Each bit configures one pin in GPIO port G.
    0=GPIO port G is secure (default); 1=GPIO port G is non-secure
0x15C SCU_IONSSET7 — I/O Non-secure Attribution Set Register7
  [15:0] PH — Set GPIO Port H to Non-secure State. Write 1 to set PH to non-secure state. Each bit configures one pin in GPIO port H.
    0=GPIO port H is secure (default); 1=GPIO port H is non-secure
0x200 SCU_NSMCTL reset 0x1000 — Non-secure State Monitor Control Register
  [13] DBGON — Monitor Counter Keep Counting When the Chip Is in Debug Mode Enable Bit
    0=The counter will be halted when the core processor is halted by ICE. (default); 1=The counter will keep counting when the core processor is halted by ICE
  [12] IDLEON — Monitor Counter Keep Counting When the Chip Is in Idle Mode Enable Bit. Note: In monitor mode, the counter is always halted when the core processor is in secure state.
    0=The counter will be halted when the chip is in idle mode; 1=The counter will keep counting when the chip is in idle mode. (default)
  [10] TMRMOD — Non-secure Monitor Mode Enable Bit
    0=Monitor mode. The counter will count down when the core processor is in non-secure state. (default); 1=Free-counting mode. The counter will keep counting no matter the core processor is in secure or non-secure state
  [9] AUTORLD — Auto Reload Non-secure State Monitor Counter When CURRNS Changing to 1
    0=Disable clearing non-secure state monitor counter automatically (default); 1=Enable clearing non-secure state monitor counter automatically when the core processor changes from secure state to non-secure state
  [8] NSMIEN — Non-secure State Monitor Interrupt Enable Bit
    0=Non-secure state monitor interrupt Disabled; 1=Non-secure state monitor interrupt Enabled
  [7:0] PRESCALE — Pre-scale Value of Non-secure State Monitor Counter
    0=Counter Disabled
0x204 SCU_NSMLOAD reset 0xFFFFFF — Non-secure State Monitor Reload Value Register
  [23:0] RELOAD — Reload Value for Non-secure State Monitor Counter. The RELOAD value will be reloaded to the counter whenever the counter counts down to 0.
0x208 SCU_NSMVAL reset 0xFFFFFF — Non-secure State Monitor Counter Value Register
  [23:0] VALUE — Counter Value of Non-secure State Monitor Counter. A write of any value clears the VALUE to 0 and also clears NSMIF.
0x20C SCU_NSMSTS — Non-secure State Monitor Status Register
  [1] NSMIF — Non-secure State Monitor Interrupt Flag. Note: This bit is cleared by writing 1.
    0=Counter does not count down to 0 since the last NSMIF has been cleared; 1=Counter counts down to 0
  [0] CURRNS ro — Current Core Processor Secure/Non-secure State (Read Only). Note: This bit can be used to monitor the current secure/non-secure state of the core processor, even if the non-secure state monitor counter is disabled.
    0=Core processor is in secure state; 1=Core processor is in non-secure state
